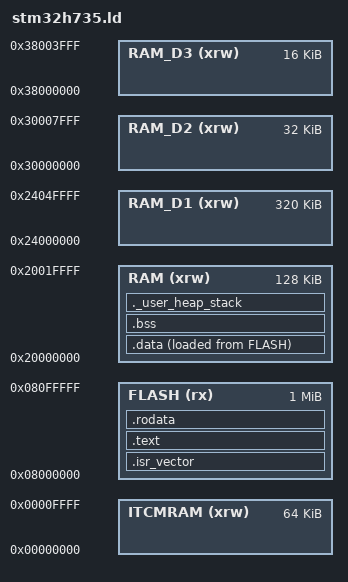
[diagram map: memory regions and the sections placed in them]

ENTRY (resetHandler)

_estack = 0x20020000;
_Min_Heap_Size = 0x200 ;
_Min_Stack_Size = 0x400 ;

MEMORY
{
  ITCMRAM (xrw)    : ORIGIN = 0x00000000,   LENGTH = 64K
  RAM     (xrw)    : ORIGIN = 0x20000000,   LENGTH = 128K
  FLASH    (rx)    : ORIGIN = 0x08000000,   LENGTH = 1024K
  RAM_D1  (xrw)    : ORIGIN = 0x24000000,   LENGTH = 320K
  RAM_D2  (xrw)    : ORIGIN = 0x30000000,   LENGTH = 32K
  RAM_D3  (xrw)    : ORIGIN = 0x38000000,   LENGTH = 16K
}

SECTIONS
{
  .isr_vector :
  {
    . = ALIGN(4);
    KEEP(*(.isr_vector))
    . = ALIGN(4);
  } >FLASH

  .text :
  {
    . = ALIGN(4);
    *(.text)
    *(.text*)
    *(.glue_7)
    *(.glue_7t)
    *(.eh_frame)

    KEEP (*(.init))
    KEEP (*(.fini))

    . = ALIGN(4);
    _etext = .;
  } >FLASH

  .rodata :
  {
    . = ALIGN(4);
    *(.rodata)
    *(.rodata*)
    . = ALIGN(4);
  } >FLASH

  _sidata = LOADADDR(.data);

  .data :
  {
    . = ALIGN(4);
    _sdata = .;
    *(.data)
    *(.data*)
    *(.RamFunc)
    *(.RamFunc*)

    . = ALIGN(4);
    _edata = .;
  } >RAM AT> FLASH

  . = ALIGN(4);
  .bss :
  {
    _sbss = .;
    __bss_start__ = _sbss;
    *(.bss)
    *(.bss*)
    *(COMMON)

    . = ALIGN(4);
    _ebss = .;
    __bss_end__ = _ebss;
  } >RAM

  ._user_heap_stack :
  {
    . = ALIGN(8);
    PROVIDE ( end = . );
    PROVIDE ( _end = . );
    . = . + _Min_Heap_Size;
    . = . + _Min_Stack_Size;
    . = ALIGN(8);
  } >RAM

  /DISCARD/ :
  {
    libc.a ( * )
    libm.a ( * )
    libgcc.a ( * )
  }

  .ARM.attributes 0 : { *(.ARM.attributes) }
}
